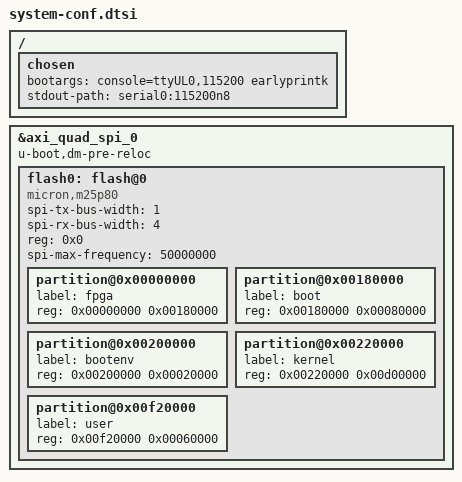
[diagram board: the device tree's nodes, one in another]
/*
 * CAUTION: This file is automatically generated by PetaLinux SDK.
 * DO NOT modify this file
 */


/ {
	chosen {
		bootargs = "console=ttyUL0,115200 earlyprintk";
		stdout-path = "serial0:115200n8";
	};
};

&axi_quad_spi_0 {
	u-boot,dm-pre-reloc;
	#address-cells = <1>;
	#size-cells = <0>;
	flash0: flash@0 {
		compatible = "micron,m25p80";
		spi-tx-bus-width=<1>;
		spi-rx-bus-width=<4>;
		reg = <0x0>;
		#address-cells = <1>;
		#size-cells = <1>;
		spi-max-frequency = <50000000>;
		partition@0x00000000 {
			label = "fpga";
			reg = <0x00000000 0x00180000>;
		};
		partition@0x00180000 {
			label = "boot";
			reg = <0x00180000 0x00080000>;
		};
		partition@0x00200000 {
			label = "bootenv";
			reg = <0x00200000 0x00020000>;
		};
		partition@0x00220000 {
			label = "kernel";
			reg = <0x00220000 0x00d00000>;
		};
		partition@0x00f20000 {
			label = "user";
			reg = <0x00f20000 0x00060000>;
		};
	};
};

